# ESP32-S31 register map
Vendor: ESPRESSIF SYSTEMS (SHANGHAI) CO., LTD.; Series: ESP32 S-Series; File version: 1
CPU: RV32IMAFC r0p0, little endian, no MPU, FPU, 0 interrupt priority bits
Address unit: 32 bits
Registers are 32-bit, read-write, reset 0x0 unless marked. A register's access mark holds for its fields unless they carry their own. Offsets are from the block's base; [hi:lo] are bit positions; lines under a group give offsets from that group; {n}, {i} and the like mark numbered series.

## LP_ADI — LP_ADI Peripheral
Base 0x20805000
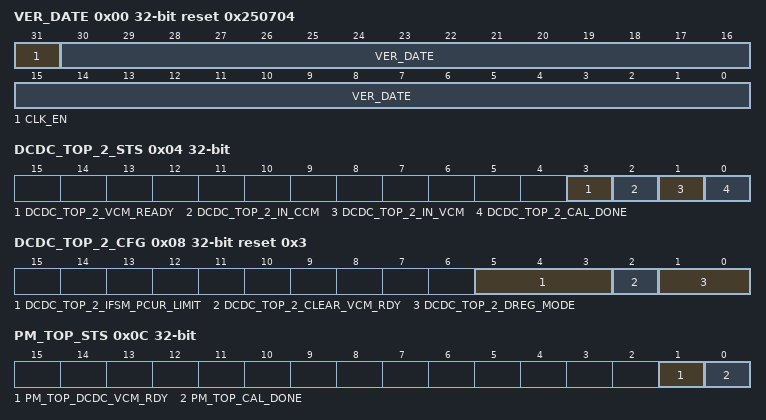
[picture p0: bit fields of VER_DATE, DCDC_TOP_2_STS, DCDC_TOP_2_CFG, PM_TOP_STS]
0x00 VER_DATE reset 0x250704 — need_des
  [31] CLK_EN — need_des
  [30:0] VER_DATE — need_des
0x04 DCDC_TOP_2_STS ro — ANALOG DCDC 2 related status
  [3] DCDC_TOP_2_VCM_READY — vcm_ready signal from dcdc 2 top
  [2] DCDC_TOP_2_IN_CCM — in ccm signal from dcdc 2 top
  [1] DCDC_TOP_2_IN_VCM — in vcm signal from dcdc 2 top
  [0] DCDC_TOP_2_CAL_DONE — cali done signal from dcdc 2 top
0x08 DCDC_TOP_2_CFG reset 0x3 — ANALOG DCDC 2 related CONFIG
  [5:3] DCDC_TOP_2_IFSM_PCUR_LIMIT — Current limit config
  [2] DCDC_TOP_2_CLEAR_VCM_RDY — 1: clear vcm rdy signal
  [1:0] DCDC_TOP_2_DREG_MODE — DCDC 2 dreg mode
0x0C PM_TOP_STS ro — ANALOG PM TOP related status
  [1] PM_TOP_DCDC_VCM_RDY — vcm_ready signal from PM TOP
  [0] PM_TOP_CAL_DONE — cali done signal from PM TOP
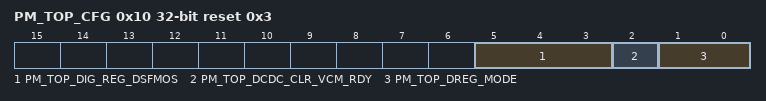
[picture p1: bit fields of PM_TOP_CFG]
0x10 PM_TOP_CFG reset 0x3 — ANALOG PM TOP related CONFIG
  [5:3] PM_TOP_DIG_REG_DSFMOS — Current limit config
  [2] PM_TOP_DCDC_CLR_VCM_RDY — 1: clear vcm rdy signal
  [1:0] PM_TOP_DREG_MODE

## LP_ANA — LP_ANA_PERI Peripheral
Base 0x20702000
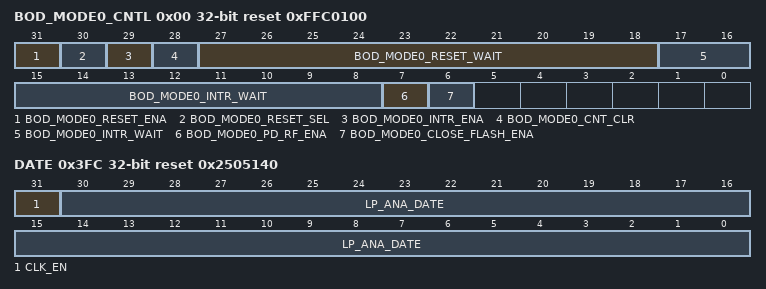
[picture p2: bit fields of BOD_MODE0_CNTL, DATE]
0x00 BOD_MODE0_CNTL reset 0xFFC0100 — need_des
  [31] BOD_MODE0_RESET_ENA — need_des
  [30] BOD_MODE0_RESET_SEL — need_des
  [29] BOD_MODE0_INTR_ENA — need_des
  [28] BOD_MODE0_CNT_CLR — need_des
  [27:18] BOD_MODE0_RESET_WAIT — need_des
  [17:8] BOD_MODE0_INTR_WAIT — need_des
  [7] BOD_MODE0_PD_RF_ENA — need_des
  [6] BOD_MODE0_CLOSE_FLASH_ENA — need_des
0x04 BOD_MODE1_CNTL — need_des
  [31] BOD_MODE1_RESET_ENA
0x08 VDD_SOURCE_CNTL reset 0x3F — need_des
  [5:0] DETMODE_SEL
0x18 PG_GLITCH_CNTL — need_des
  [31:26] POWER_GLITCH_RESET_ENA
0x1C FIB_ENABLE reset 0xFFFFFFFF — need_des
  [31:0] ANA_FIB_ENA
0x20 INT_RAW — need_des
  [31] BOD_MODE0
0x24 INT_ST ro — need_des
  [31] BOD_MODE0
0x28 INT_ENA — need_des
  [31] BOD_MODE0
0x2C INT_CLR wo — need_des
  [31] BOD_MODE0 write-1-clears
0x30 LP_INT_RAW — need_des
  [31] BOD_MODE0
0x34 LP_INT_ST ro — need_des
  [31] BOD_MODE0
0x38 LP_INT_ENA — need_des
  [31] BOD_MODE0
0x3C LP_INT_CLR wo — need_des
  [31] BOD_MODE0 write-1-clears
0x3FC DATE reset 0x2505140 — need_des
  [31] CLK_EN — need_des
  [30:0] LP_ANA_DATE — need_des

## LP_APM — Low-power Access Permission Management Controller
Base 0x20706C00
0x00 REGION_FILTER_EN reset 0x1 — Region filter enable register
  [7:0] REGION_FILTER_EN — Configure bit 0(0-7) to enable region 0.\\ 0: disable \\ 1: enable \\
{0x4+0xC*i} REGION{i}_ADDR_START (i=0..7) — Region address register
  [31:0] REGION_ADDR_START — Configures start address of region %s
{0x8+0xC*i} REGION{i}_ADDR_END (i=0..7) reset 0xFFFFFFFF — Region address register
  [31:0] REGION_ADDR_END — Configures end address of region %s
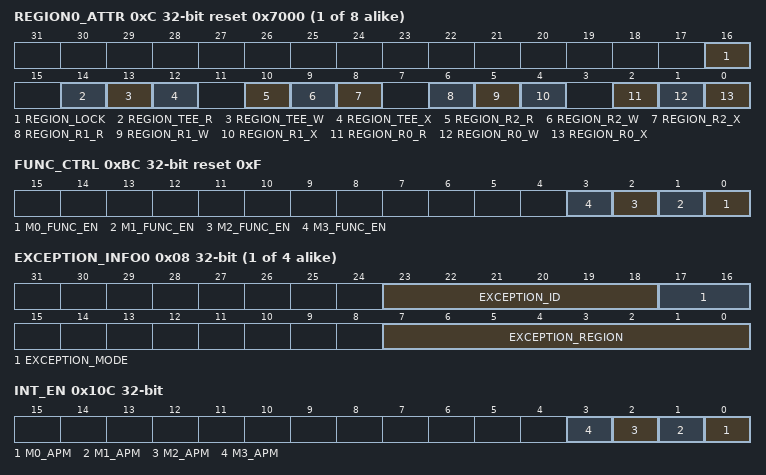
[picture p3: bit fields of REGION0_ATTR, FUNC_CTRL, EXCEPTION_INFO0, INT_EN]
{0xC+0xC*i} REGION{i}_ATTR (i=0..7) reset 0x7000 — Region access authority attribute register
  [16] REGION_LOCK — Set 1 to lock region0 configuration
  [14] REGION_TEE_R — Configures the read authority of TEE_MODE in region %s.
  [13] REGION_TEE_W — Configures the write authority of TEE_MODE in region %s.
  [12] REGION_TEE_X — Configures the execution authority of TEE_MODE in region %s.
  [10] REGION_R2_R — Configures the read authority of REE_MODE 2 in region %s.
  [9] REGION_R2_W — Configures the write authority of REE_MODE 2 in region %s.
  [8] REGION_R2_X — Configures the execution authority of REE_MODE 2 in region %s.
  [6] REGION_R1_R — Configures the read authority of REE_MODE 1 in region %s.
  [5] REGION_R1_W — Configures the write authority of REE_MODE 1 in region %s.
  [4] REGION_R1_X — Configures the execution authority of REE_MODE 1 in region %s.
  [2] REGION_R0_R — Configures the read authority of REE_MODE 0 in region %s.
  [1] REGION_R0_W — Configures the write authority of REE_MODE 0 in region %s.
  [0] REGION_R0_X — Configures the execution authority of REE_MODE 0 in region %s.
0xBC FUNC_CTRL reset 0xF — APM function control register
  [n] M{n}_FUNC_EN (n=0..3) — PMS M{n} function enable
{0xC0+0x14*i} M{i} (i=0..3) group — Cluster M{i}, containing M?_STATUS, M?_STATUS_CLR, M?_EXCEPTION_INFO0, M?_EXCEPTION_INFO1
  0x00 STATUS ro — M0 status register
    [1:0] EXCEPTION_STATUS — Represents exception status.\\ bit0: 1 represents authority_exception \\ bit1: 1 represents space_exception \\
  0x04 STATUS_CLR wo — M0 status clear register
    [0] EXCEPTION_STATUS_CLR — Configures to clear exception status
  0x08 EXCEPTION_INFO0 ro — M0 exception_info0 register
    [23:18] EXCEPTION_ID — Represents exception id information
    [17:16] EXCEPTION_MODE — Represents exception mode
    [7:0] EXCEPTION_REGION — Represents exception region
  0x0C EXCEPTION_INFO1 ro — M0 exception_info1 register
    [31:0] EXCEPTION_ADDR — Represents exception addr
0x10C INT_EN — APM interrupt enable register
  [n] M{n}_APM (n=0..3) — Configures APM M{n} interrupt enable.\\ 0: disable \\ 1: enable \\
0x110 BUS_ERR_CONF — APM interrupt enable register
  [0] BUS_ERR_RESP_EN — Configures whether return error response to cpu when access blocked 0: disable error response \\ 1: enable error response \\
0x3F8 CLOCK_GATE reset 0x1 — Clock gating register
  [0] CLK_EN — Configures whether to keep the clock always on.\\ 0: enable automatic clock gating \\ 1: keep the clock always on \\
0x3FC DATE reset 0x2506260 — Version control register
  [27:0] DATE
